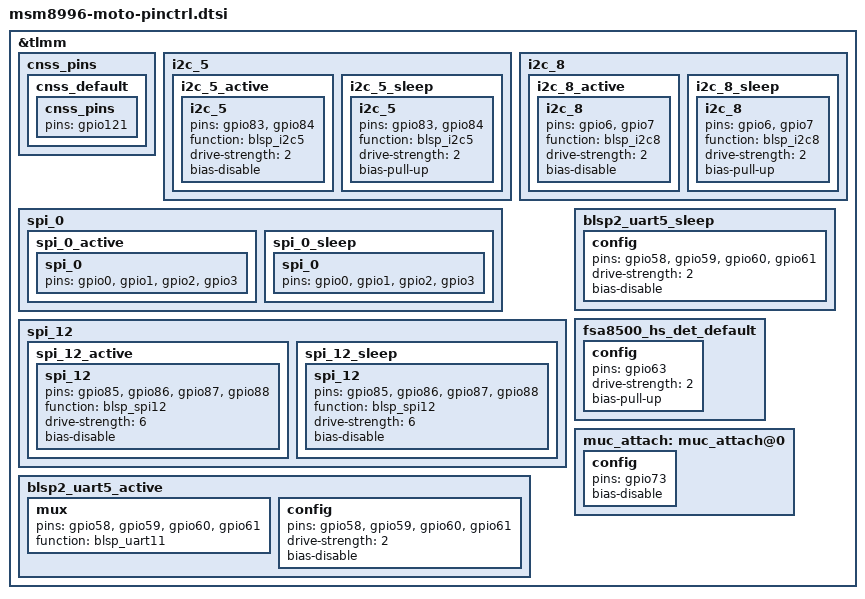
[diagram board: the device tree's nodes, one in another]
/* Copyright (c) 2015, Motorola Mobility Inc. All rights reserved.
 *
 * This program is free software; you can redistribute it and/or modify
 * it under the terms of the GNU General Public License version 2 and
 * only version 2 as published by the Free Software Foundation.
 *
 * This program is distributed in the hope that it will be useful,
 * but WITHOUT ANY WARRANTY; without even the implied warranty of
 * MERCHANTABILITY or FITNESS FOR A PARTICULAR PURPOSE.  See the
 * GNU General Public License for more details.
 */

&tlmm {
	cnss_pins {
		cnss_default: cnss_default {
			cnss_pins {
				pins = "gpio121";
			};
		};
	};

	i2c_5 {
		i2c_5_active: i2c_5_active {
			i2c_5 {
				pins = "gpio83", "gpio84";
				function = "blsp_i2c5";
				drive-strength = <2>;
				bias-disable;
			};
		};

		i2c_5_sleep: i2c_5_sleep {
			i2c_5 {
				pins = "gpio83", "gpio84";
				function = "blsp_i2c5";
				drive-strength = <2>;
				bias-pull-up;
			};
		};
	};

	i2c_8 {
		i2c_8_active: i2c_8_active {
			i2c_8 {
				pins = "gpio6", "gpio7";
				function = "blsp_i2c8";
				drive-strength = <2>;
				bias-disable;
			};
		};

		i2c_8_sleep: i2c_8_sleep {
			i2c_8 {
				pins = "gpio6", "gpio7";
				function = "blsp_i2c8";
				drive-strength = <2>;
				bias-pull-up;
			};
		};
	};

	/* These are defined in msm8996-pinctrl.dtsi but we need to add CS on
	 * GPIO2 since our reference design includes it.
	 */
	spi_0 {
		spi_0_active: spi_0_active {
			spi_0 {
				pins = "gpio0", "gpio1", "gpio2", "gpio3";
			};
		};

		spi_0_sleep: spi_0_sleep {
			spi_0 {
				pins = "gpio0", "gpio1", "gpio2", "gpio3";
			};
		};
	};

	spi_12 {
		spi_12_active: spi_12_active {
			spi_12 {
				pins = "gpio85", "gpio86", "gpio87", "gpio88";
				function = "blsp_spi12";
				drive-strength = <6>;
				bias-disable;
			};
		};

		spi_12_sleep: spi_12_sleep {
			spi_12 {
				pins = "gpio85", "gpio86", "gpio87", "gpio88";
				function = "blsp_spi12";
				drive-strength = <6>;
				bias-disable;
			};
		};
	};

	blsp2_uart5_active: blsp2_uart5_active {
		mux {
			pins = "gpio58", "gpio59", "gpio60", "gpio61";
			function = "blsp_uart11";
		};

		config {
			pins = "gpio58", "gpio59", "gpio60", "gpio61";
			drive-strength = <2>;
			bias-disable;
		};
	};

	blsp2_uart5_sleep: blsp2_uart5_sleep {
		config {
			pins = "gpio58", "gpio59", "gpio60", "gpio61";
			drive-strength = <2>;
			bias-disable;
		};
	};

	fsa8500_hs_det_default: fsa8500_hs_det_default {
		config {
			pins = "gpio63";
			drive-strength = <2>;
			bias-pull-up;
		};
	};

	muc_attach: muc_attach@0 {
		config {
			pins = "gpio73";
			bias-disable;
		};
	};
};
